# nrf7140_wificore register map
Vendor: Nordic Semiconductor; Series: nRF71; File version: 1
Registers are 32-bit, read-write, reset 0x0 unless marked. A register's access mark holds for its fields unless they carry their own. Offsets are from the block's base; [hi:lo] are bit positions; lines under a group give offsets from that group.

## RPUPHY (part 3 of 8) — WIFICore RPU PHY peripherals
Base 0x48080000; alternate view of RPUMAC
0x8000 WLAN_CTRL group — Unspecified
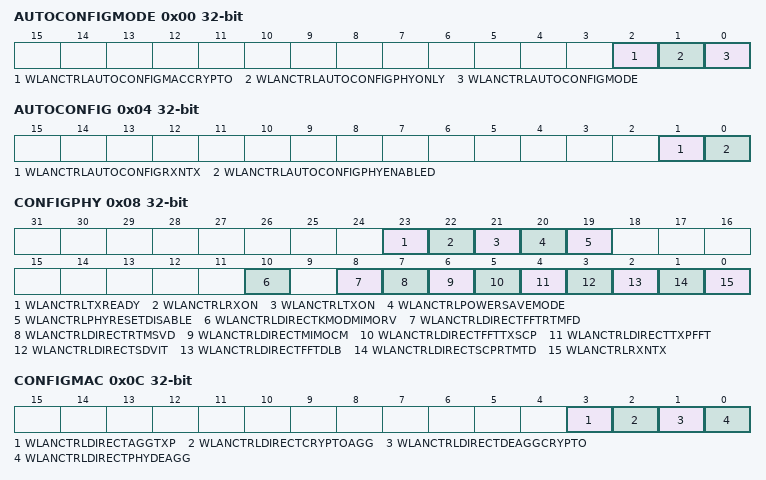
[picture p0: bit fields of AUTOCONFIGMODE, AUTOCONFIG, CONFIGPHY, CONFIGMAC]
  0x00 AUTOCONFIGMODE — WLAN CTRL AUTO CONFIG MODE
    [2] WLANCTRLAUTOCONFIGMACCRYPTO — Enable auto-configuration MAC with or without Crypto
      0=Auto-configure MAC pipeline with Crypto; 1=AutoConfigureMacPip1 (Auto-configure MAC pipeline without Crypto)
    [1] WLANCTRLAUTOCONFIGPHYONLY — Enable auto-configuration for PHY+MAC or PHY-only
      0=Auto-configure full PHY+MAC pipeline; 1=Auto-configure only PHY pipeline
    [0] WLANCTRLAUTOCONFIGMODE — Select mode used for automatic configuration:
      0=Automatic PHY configuration through WLAN_CTRL_AUTO_CONFIG register; 1=AutomaticPhyConfigur1 (Automatic PHY configuration using direct lines from MAC controller)
  0x04 AUTOCONFIG — WLAN CTRL AUTO CONFIG
    [1] WLANCTRLAUTOCONFIGRXNTX — Configure Wi-Fi RX or TX mode:
      0=Tx; 1=Rx
    [0] WLANCTRLAUTOCONFIGPHYENABLED — Enable PHY for either RX or TX:
      0=PhyDisabled; 1=PhyEnabled
  0x08 CONFIGPHY — WLAN CTRL CONFIG PHY
    [23] WLANCTRLTXREADY — Enable TX-SCP output:
      0=Disabled; 1=Enabled
    [22] WLANCTRLRXON — Set RF RX on:
      0=RxOff; 1=RxOn
    [21] WLANCTRLTXON — Set RF TX on:
      0=TxOff; 1=TxOn
    [20] WLANCTRLPOWERSAVEMODE — Enable Power Save mode:
      0=Disabled; 1=Enabled
    [19] WLANCTRLPHYRESETDISABLE — Control for automatic PHY reset (RX mode):
      0=PHY reset will be automatically generated; 1=No automatic PHY reset is generated
    [10] WLANCTRLDIRECTKMODMIMORV — Select whether MIMO RV input is from DMA channels or a direct connection between peripherals:
      0=DmaChannels; 1=Direct connection between peripherals
    [8] WLANCTRLDIRECTFFTRTMFD — Select whether FFT data input to RTM FD are from DMA channels or a direct connection from FFT:
      0=DmaChannels; 1=Direct connection between peripherals
    [7] WLANCTRLDIRECTRTMSVD — Select whether WLAN SVD input is from DMA channels or a direct connection between peripherals:
      0=DmaChannels; 1=Direct connection between peripherals
    [6] WLANCTRLDIRECTMIMOCM — Select whether MIMO Channel Matrix input is from DMA channels or a direct connection between peripherals:
      0=DmaChannels; 1=Direct connection between peripherals
    [5] WLANCTRLDIRECTFFTTXSCP — Select whether FFT output and TX-SCP input are to/from DMA channels or a direct connection between peripherals:
      0=DmaChannels; 1=Direct connection between peripherals
    [4] WLANCTRLDIRECTTXPFFT — Select whether TXP output and FFT input are to/from DMA channels or a direct connection between peripherals:
      0=DmaChannels; 1=Direct connection between peripherals
    [3] WLANCTRLDIRECTSDVIT — Select whether Stream Deparser outputs and Viterbi Decoder inputs are to/from DMA channels or a direct connection between peripherals:
      0=DmaChannels; 1=Direct connection between peripherals
    [2] WLANCTRLDIRECTFFTDLB — Select whether FFT output and DLB input are to/from DMA channels or a direct connection between peripherals:
      0=DmaChannels; 1=Direct connection between peripherals
    [1] WLANCTRLDIRECTSCPRTMTD — Select whether SCP outputs and RTM_TD input are to/from DMA channels or a direct connection between peripherals:
      0=DmaChannels; 1=Direct connection between peripherals
    [0] WLANCTRLRXNTX — Configure Wi-Fi RX or TX mode:
      0=Tx; 1=Rx
  0x0C CONFIGMAC — WLAN CTRL CONFIG MAC
    [all] fields
      0=DmaChannels; 1=Direct connection between peripherals
    [3] WLANCTRLDIRECTAGGTXP — Select whether Aggregation output and TXP input are to/from DMA channels or a direct connection between peripherals:
    [2] WLANCTRLDIRECTCRYPTOAGG — Select whether Crypto output and Aggregation input are to/from DMA channels or a direct connection between peripherals:
    [1] WLANCTRLDIRECTDEAGGCRYPTO — Select whether Deaggregation output and Crypto input are to/from DMA channels or a direct connection between peripherals:
    [0] WLANCTRLDIRECTPHYDEAGG — Select whether PHY outputs and Deaggregation inputs are to/from DMA channels or a direct connection between peripherals:
  0x10 TXHOLDOFF — WLAN CTRL TX HOLDOFF
    [13:0] WLANCTRLTXHOLDOFF — Specify TX hold-off to delay TX output to the DAC.Units are core clock cycles.
  0x14 TXEXTRAHOLDOFF — WLAN CTRL TX EXTRA HOLDOFF
    [13:0] WLANCTRLTXEXTRAHOLDOFF — Specify extra TX hold-off to delay TX output to the DAC.This extra hold-off can be selected through the TX vector.Units are core clock cycles.
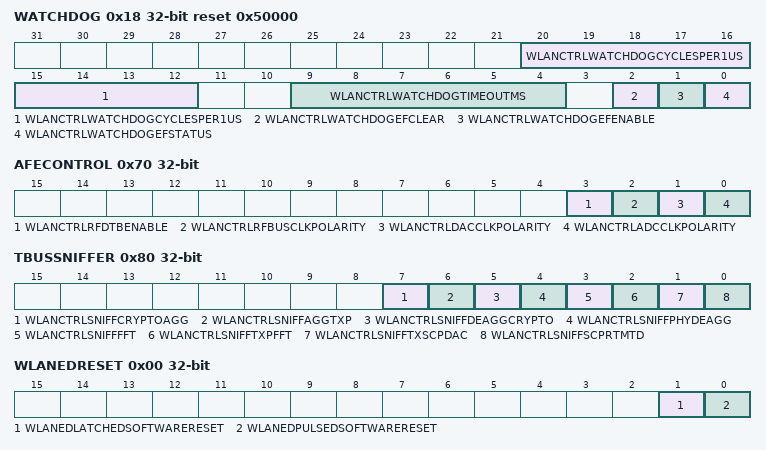
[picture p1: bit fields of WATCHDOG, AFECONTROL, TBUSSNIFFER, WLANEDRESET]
  0x18 WATCHDOG reset 0x50000 — WLAN CTRL WATCHDOG
    [20:12] WLANCTRLWATCHDOGCYCLESPER1US — Configure the number of core clock cycles per microsecond.
    [9:4] WLANCTRLWATCHDOGTIMEOUTMS — Specify watchdog timeout in milliseconds. Zero means the watchdog event flag is disabled.
    [2] WLANCTRLWATCHDOGEFCLEAR — WLAN watchdog event flag acknowledge/clear.Write 1 to clear WLAN_CTRL_WATCHDOG_EF_STATUS.Writing 0 has no effect.
    [1] WLANCTRLWATCHDOGEFENABLE — WLAN watchdog event flag enable.ANDed with WLAN_CTRL_WATCHDOG_EF_STATUS before generating EF output from block.
    [0] WLANCTRLWATCHDOGEFSTATUS — WLAN watchdog event flag status.Latched high when watchdog timer reaches programmed thresholdCan be forced high by writing 1 to this register for debug purposes (to test event flag connectivity in hardware and software).
  0x1C DEBUGPHYRESET ro — WLAN CTRL DEBUG PHY RESET
    [5:0] WLANCTRLDEBUGPHYRESET — Live state of the PHY reset signals0: PHY reset1: EDAGC reset2: SCP reset3: TD reset4: FD reset5: RXP reset
  0x20 DEBUGGING — WLAN CTRL DEBUG
    [1:0] WLANCTRLDEBUG — Enable debug registers PHY_VALID, PHY_ENABLE, MAC_VALID and MAC_ENABLE
      0=Disabled; 1=ValidEnable; 2=Sticky(Valid), Sticky(Enable); 3=Valid & Enable, Sticky(Valid & Enable)
  0x24 DEBUGPHYVALID ro — WLAN CTRL DEBUG PHY VALID
    [10:0] WLANCTRLDEBUGPHYVALID — Live state of the PHY valid flow control signals0: TXFD Input1: TXFD Output2: RXTD Input3: RXTD OFDM Output4: RXTD DSSS Output5: FFT Input6: FFT Output7: TXTD Input8: TXTD Output9: RXFD FFT Input10: RXFD Output
  0x28 DEBUGPHYENABLE ro — WLAN CTRL DEBUG PHY ENABLE
    [10:0] WLANCTRLDEBUGPHYENABLE — Live state of the PHY enable flow control signals0: TXFD Input1: TXFD Output2: RXTD Input3: RXTD OFDM Output4: RXTD DSSS Output5: FFT Input6: FFT Output7: TXTD Input8: TXTD Output9: RXFD FFT Input10: RXFD Output
  0x2C DEBUGMACVALID ro — WLAN CTRL DEBUG MAC VALID
    [6:0] WLANCTRLDEBUGMACVALID — Live state of the MAC valid flow control signals0: AGG WR1: AGG RD2: DEAGG WR3: DEAGG RD4: CRYPTO WR5: CRYPTO RD6: DECOMP WR
  0x30 DEBUGMACENABLE ro — WLAN CTRL DEBUG MAC ENABLE
    [6:0] WLANCTRLDEBUGMACENABLE — Live state of the MAC enable flow control signals0: AGG WR1: AGG RD2: DEAGG WR3: DEAGG RD4: CRYPTO WR5: CRYPTO RD6: DECOMP WR
  0x34 CCABUSYCOUNT0 — WLAN CTRL CCA BUSY COUNT 0
    [0] WLANCTRLCCABUSYCOUNTENA — Enable / disable CCA busy window counter. When disabled counter is set to zero.
  0x38 CCABUSYCOUNT1 ro — WLAN CTRL CCA BUSY COUNT 1
    [23:0] WLANCTRLCCABUSYCOUNTER — CCA busy window counter in Core clock cycles.
  0x3C NUMPAYLOADBYTESFORDEASSERTION — WLAN CTRL NUM PAYLOAD BYTES FOR DEASSERTION
    [5:0] WLANCTRLNUMPAYLOADBYTESFORDEASSERTION — Number of payload bytes after which PHY_RX_Request is deasserted.This value is set such that PHY-RX-Request is asserted till MAC hardware checkswhether MAC address of receiving packet is matching with expected address,i.e., this number should cover more than 10 bytes of MPDU.Typical value is 20 considering A-MPDU and some margin for MAC address matching.
  0x40 TMCOUNTERMSB — WLAN CTRL TM COUNTER MSB
    [23:0] WLANCTRLTMCOUNTERMSB — MSB of Counter used for time measurement snapshots
  0x44 TMCOUNTERLSB — WLAN CTRL TM COUNTER LSB
    [23:0] WLANCTRLTMCOUNTERLSB — LSB of Counter used for time measurement snapshots
  0x48 ADCFIRSTSAMPLESNAPSHOTMSB ro — WLAN CTRL ADC FIRST SAMPLE SNAPSHOT MSB
    [23:0] WLANCTRLADCFIRSTSAMPLESNAPSHOTMSB — MSB of snapshot of time measurement counter, taken when first sample of ADC goes valid
  0x4C ADCFIRSTSAMPLESNAPSHOTLSB ro — WLAN CTRL ADC FIRST SAMPLE SNAPSHOT LSB
    [23:0] WLANCTRLADCFIRSTSAMPLESNAPSHOTLSB — LSB of snapshot of time measurement counter, taken when first sample of ADC goes valid
  0x50 TMCOUNTERCTRL — WLAN CTRL TM COUNTER CTRL
    [0] WLANCTRLTMCOUNTERENABLE — Enable signal for 48-bit time measurement counter
  0x54 TXABORTCONTROL — WLAN CTRL TX ABORT CONTROL
    [0] WLANCTRLTXABORTCONTROL — Control to assert wlan_ctrl_rx_on when TX_ABORT is received.
      0=Do not assert wlan_ctrl_rx_on; 1=Assert wlan_ctrl_rx_on when abort_status is high
  0x58 OFDMRTMSCPEOPSNAPSHOTMSB ro — WLAN CTRL OFDM RTM SCP EOP SNAPSHOT MSB
    [23:0] WLANCTRLOFDMRTMSCPEOPSNAPSHOTMSB — MSB of snapshot of time measurement counter, taken when OFDM Receiver Training Mode - SCP EOP goes high
  0x5C OFDMRTMSCPEOPSNAPSHOTLSB ro — WLAN CTRL OFDM RTM SCP EOP SNAPSHOT LSB
    [23:0] WLANCTRLOFDMRTMSCPEOPSNAPSHOTLSB — LSB of snapshot of time measurement counter, taken when OFDM Receiver Training Mode - SCP EOP goes high
  0x60 OFDMRTMFDEOPSNAPSHOTMSB ro — WLAN CTRL OFDM RTM FD EOP SNAPSHOT MSB
    [23:0] WLANCTRLOFDMRTMFDEOPSNAPSHOTMSB — MSB of snapshot of time measurement counter, taken when OFDM Receiver Training Mode - FD EOP goes high
  0x64 OFDMRTMFDEOPSNAPSHOTLSB ro — WLAN CTRL OFDM RTM FD EOP SNAPSHOT LSB
    [23:0] WLANCTRLOFDMRTMFDEOPSNAPSHOTLSB — LSB of snapshot of time measurement counter, taken when OFDM Receiver Training Mode - FD EOP goes high
  0x68 TMCOUNTERSNAPSHOTMSB — WLAN CTRL TM COUNTER SNAPSHOT MSB
    [23:0] WLANCTRLTMCOUNTERSNAPSHOTMSB — MSB of snapshot of time measurement counter, taken when either WLAN_CTRL_TM_COUNTER_SNAPSHOT_MSB or WLAN_CTRL_TM_COUNTER_SNAPSHOT_LSB is written
  0x6C TMCOUNTERSNAPSHOTLSB — WLAN CTRL TM COUNTER SNAPSHOT LSB
    [23:0] WLANCTRLTMCOUNTERSNAPSHOTLSB — LSB of snapshot of time measurement counter, taken when either WLAN_CTRL_TM_COUNTER_SNAPSHOT_MSB or WLAN_CTRL_TM_COUNTER_SNAPSHOT_LSB is written
  0x70 AFECONTROL — WLAN CTRL AFE CONTROL
    [3] WLANCTRLRFDTBENABLE — RF Digital Test Bus enable
      0=RfDtbNotEnabled; 1=RfDrbEnabled
    [2] WLANCTRLRFBUSCLKPOLARITY — RF bus clock polarity:
      0=PositiveEdge; 1=NegativeEdge
    [1] WLANCTRLDACCLKPOLARITY — DAC sample clock polarity:
      0=PositiveEdge; 1=NegativeEdge
    [0] WLANCTRLADCCLKPOLARITY — ADC sample clock polarity:
      0=PositiveEdge; 1=NegativeEdge
  0x74 RFPMUUP — WLAN CTRL RF PMU UP
    [0] WLANCTRLRFPMUUP — Enable RF:
      0=Not enabled (PMU_UP_P=0 and PMU_UP_N=1); 1=Enabled (PMU_UP_P=1 and PMU_UP_N=0)
  0x78 RFBANDSEL — WLAN CTRL RF BAND SEL
    [0] WLANCTRLRFBANDSEL — Select between low band and high band RF:
      0=LowBand; 1=HighBand
  0x80 TBUSSNIFFER — WLAN CTRL TBUS SNIFFER
    [all] fields
      0=NotSniffed; 1=Sniff Tbus connection whilst in direct connection
    [7] WLANCTRLSNIFFCRYPTOAGG — Select whether Crypto outputs and Agg input are output to the EDC during direct connection:
    [6] WLANCTRLSNIFFAGGTXP — Select whether AGG outputs and TXP input are output to the EDC during direct connection:
    [5] WLANCTRLSNIFFDEAGGCRYPTO — Select whether DEAGG outputs and CRYPTO input are output to the EDC during direct connection:
    [4] WLANCTRLSNIFFPHYDEAGG — Select whether PHY outputs and DEAGG input are output to the EDC during direct connection:
    [3] WLANCTRLSNIFFFFT — Select whether FFT outputs and MIMO/TXSCP input are output to the EDC during direct connection:
    [2] WLANCTRLSNIFFTXPFFT — Select whether TXP outputs and FFT input are output to the EDC during direct connection:
    [1] WLANCTRLSNIFFTXSCPDAC — Select whether TX-SCP outputs and DAC input are output to the EDC during direct connection:
    [0] WLANCTRLSNIFFSCPRTMTD — Select whether SCP outputs and RTM_TD input are output to the EDC during direct connection:
  0xFC WLANCOREREVISION ro
    [23:0] WLANCOREREVISION — WiFi Core revision : Major(8).Minor(8).Maintenance(8)
0x9000 WIFICOREED group — Unspecified
  0x00 WLANEDRESET
    [1] WLANEDLATCHEDSOFTWARERESET — Latched software reset.
    [0] WLANEDPULSEDSOFTWARERESET — Self-clearing software reset.
  0x04 WLANEDFSMCONFIG reset 0x1
    [0] EDENABLE — Enable the ED module.
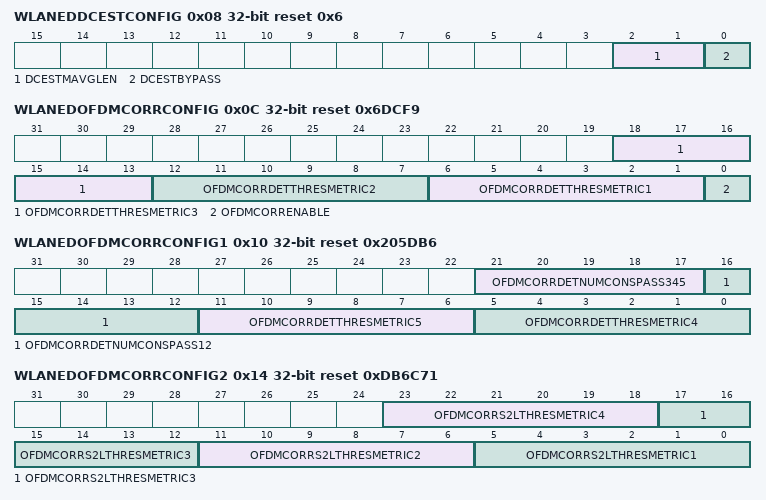
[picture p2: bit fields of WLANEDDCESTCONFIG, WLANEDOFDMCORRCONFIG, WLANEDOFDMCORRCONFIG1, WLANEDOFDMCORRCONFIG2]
  0x08 WLANEDDCESTCONFIG reset 0x6
    [2:1] DCESTMAVGLEN — DC estimation moving averager filter length:
      0=1; 1=2; 2=4; 3=8
    [0] DCESTBYPASS — Enable the WLAN ED DC EST module.
  0x0C WLANEDOFDMCORRCONFIG reset 0x6DCF9
    [18:13] OFDMCORRDETTHRESMETRIC3 — OFDM correlation detection metric 3 threshold. It has a range of -31 .. 0. Default value is -10.
    [12:7] OFDMCORRDETTHRESMETRIC2 — OFDM correlation detection metric 2 threshold. It has a range of -31 .. 0. Default value is -7.
    [6:1] OFDMCORRDETTHRESMETRIC1 — OFDM correlation detection metric 1 threshold. It has a range of -31 .. 0. Default value is -4.
    [0] OFDMCORRENABLE — Enable the WLAN ED OFDM correlation module.
  0x10 WLANEDOFDMCORRCONFIG1 reset 0x205DB6
    [21:17] OFDMCORRDETNUMCONSPASS345 — Number of consecutive metric pass for OFDM detection. It has a range of 0 .. 31.
    [16:12] OFDMCORRDETNUMCONSPASS12 — Number of consecutive metric pass for OFDM detection. It has a range of 0 .. 31.
    [11:6] OFDMCORRDETTHRESMETRIC5 — OFDM correlation detection metric 5 threshold. It has a range of -31 .. 0. Default value is -10.
    [5:0] OFDMCORRDETTHRESMETRIC4 — OFDM correlation detection metric 4 threshold. It has a range of -31 .. 0. Default value is -10.
  0x14 WLANEDOFDMCORRCONFIG2 reset 0xDB6C71
    [23:18] OFDMCORRS2LTHRESMETRIC4 — OFDM correlation S2l metric 4 threshold. It has a range of -31 .. 0. Default value is -10.
    [17:12] OFDMCORRS2LTHRESMETRIC3 — OFDM correlation S2l metric 3 threshold. It has a range of -31 .. 0. Default value is -10.
    [11:6] OFDMCORRS2LTHRESMETRIC2 — OFDM correlation S2l metric 2 threshold. It has a range of -31 .. 0. Default value is -15.
    [5:0] OFDMCORRS2LTHRESMETRIC1 — OFDM correlation S2l metric 1 threshold. It has a range of -31 .. 0. Default value is -15.
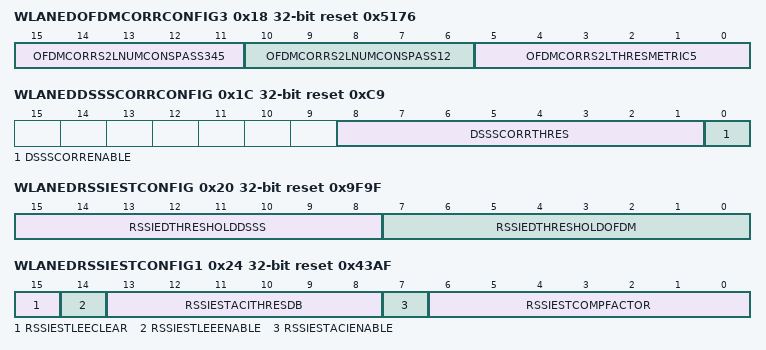
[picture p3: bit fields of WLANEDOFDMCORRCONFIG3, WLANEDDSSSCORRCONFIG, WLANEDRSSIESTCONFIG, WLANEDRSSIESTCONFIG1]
  0x18 WLANEDOFDMCORRCONFIG3 reset 0x5176
    [15:11] OFDMCORRS2LNUMCONSPASS345 — Number of consecutive pass for S2L detection. It has a range of 0 .. 31.
    [10:6] OFDMCORRS2LNUMCONSPASS12 — Number of consecutive pass for S2L detection. It has a range of 0 .. 31.
    [5:0] OFDMCORRS2LTHRESMETRIC5 — OFDM correlation S2l metric 5 threshold. It has a range of -31 .. 0. Default value is -10.
  0x1C WLANEDDSSSCORRCONFIG reset 0xC9
    [8:1] DSSSCORRTHRES — DSSS correlation threshold. It has a range of 0 .. 255.
    [0] DSSSCORRENABLE — Enable the WLAN ED DSSS correlation module.
  0x20 WLANEDRSSIESTCONFIG reset 0x9F9F
    [15:8] RSSIEDTHRESHOLDDSSS — RSSI estimation threshold (dBm) to be used when dsssDetected is true. It has a range of -128 .. 127. Default value is -97.
    [7:0] RSSIEDTHRESHOLDOFDM — RSSI estimation threshold (dBm) to be used when ofdmDetected is true. It has a range of -128 .. 127. Default value is -97.
  0x24 WLANEDRSSIESTCONFIG1 reset 0x43AF
    [15] RSSIESTLEECLEAR — Clear Low Energy Event.
    [14] RSSIESTLEEENABLE — Enable Low Energy Event.
    [13:8] RSSIESTACITHRESDB — RSSI estimation ACI dB threshold. It has a range of 0 .. 63.
    [7] RSSIESTACIENABLE — Enable Adjacent Channel Interference.
    [6:0] RSSIESTCOMPFACTOR — RSSI estimation compensation factor (F) in dB.It has a range of 0 .. 127.This is used in computing the RSSI given the variance and corresponding analog gain in dB.rssiInDbm = varDb - gainDb - RSSI_EST_COMP_FACTOR
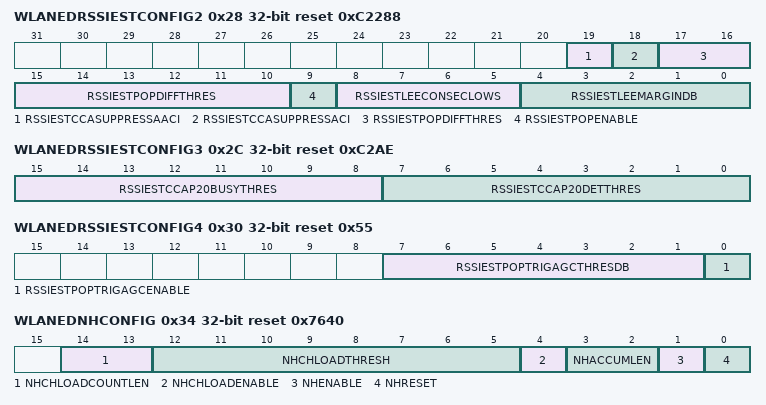
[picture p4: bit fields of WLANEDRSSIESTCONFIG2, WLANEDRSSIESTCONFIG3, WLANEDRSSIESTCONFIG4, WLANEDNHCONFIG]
  0x28 WLANEDRSSIESTCONFIG2 reset 0xC2288
    [19] RSSIESTCCASUPPRESSAACI — If this bit is '1', then CCA will be suppressed ('0') if AACI detected signal is '1'. Else CCA behaves normally.
    [18] RSSIESTCCASUPPRESSACI — If this bit is '1', then CCA will be suppressed ('0') if ACI detected signal is '1'. Else CCA behaves normally.
    [17:10] RSSIESTPOPDIFFTHRES — Packet over packet difference threshold. It has a range of 0 .. 255.
    [9] RSSIESTPOPENABLE — Enable Packet Over Packet.
    [8:5] RSSIESTLEECONSECLOWS — Number of consecutive lows for Low Energy Event. It has a range of 0 .. 15.
    [4:0] RSSIESTLEEMARGINDB — Low Energy Event dB margin. It has a range of 0 .. 31.
  0x2C WLANEDRSSIESTCONFIG3 reset 0xC2AE
    [15:8] RSSIESTCCAP20BUSYTHRES — Clear Channel Assessment busy threshold. It has a range of -127 .. 0. Default value is -62.
    [7:0] RSSIESTCCAP20DETTHRES — Clear Channel Assessment detection threshold. It has a range of -127 .. 0. Default value is -82.
  0x30 WLANEDRSSIESTCONFIG4 reset 0x55
    [7:1] RSSIESTPOPTRIGAGCTHRESDB — POP trigger for AGC threshold. It has a range of 0 .. 127. Default value is 42.
    [0] RSSIESTPOPTRIGAGCENABLE — Enable POP trigger generation for AGC when POP event.
  0x34 WLANEDNHCONFIG reset 0x7640
    [14:13] NHCHLOADCOUNTLEN — Noise histogram channel load length:
      0=2121; 1=2161; 2=2201; 3=2241
    [12:5] NHCHLOADTHRESH — Noise histogram channel load threshold. It has a range from -127 .. 0.
    [4] NHCHLOADENABLE — Enable noise histogram channel load counter.
    [3:2] NHACCUMLEN — Set the noise histogram accumulation length:
      0=2101; 1=2151; 2=2181; 3=2201
    [1] NHENABLE — Enable the noise histogram computation (Enable RSSI estimation accumulation).
    [0] NHRESET — Reset the noise histogram accumulator.
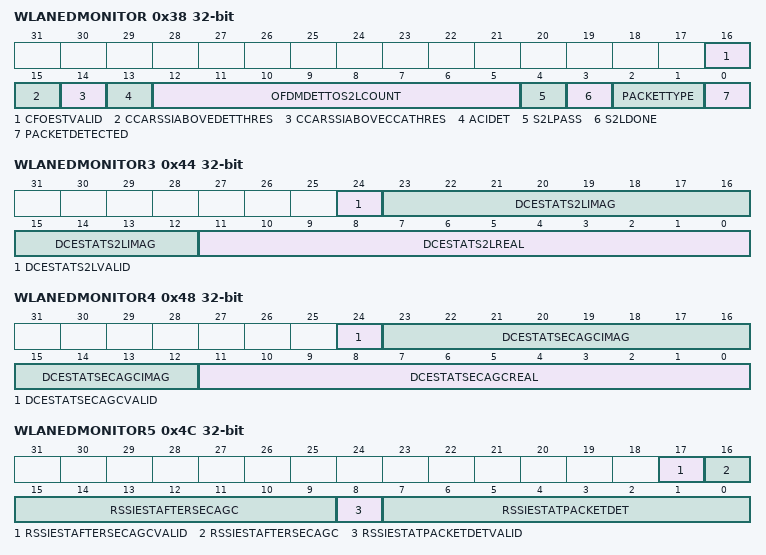
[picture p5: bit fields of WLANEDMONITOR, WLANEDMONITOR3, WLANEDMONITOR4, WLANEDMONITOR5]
  0x38 WLANEDMONITOR ro
    [16] CFOESTVALID — '1' indicates CFO estimation is completed
    [15] CCARSSIABOVEDETTHRES — '1' indicates the RSSI is above the Detection threshold (-82dBm)
    [14] CCARSSIABOVECCATHRES — '1' indicates the RSSI is above the CCA threshold (-62dBm)
    [13] ACIDET — '1' indicates an ACI signal is present and hence ED detections will not happen
    [12:5] OFDMDETTOS2LCOUNT — Contains the count in num of 20MHz samples from the time pktDetected happens to s2lPass
    [4] S2LPASS — Holds the value of s2l pass/fail status. If '1' s2l Pass, '0' s2l fail(timeout). This is valid only when S2L_EVENT is high
    [3] S2LDONE — '1' indicates s2l Event has occurred (either s2lPass or s2lFail)
    [2:1] PACKETTYPE — Indicates the type of packet detected:
      0=Unknown; 1=Ofdm; 2=Dsss
    [0] PACKETDETECTED — '1' indicates either OFDM/DSSS packet has been detected and TD processing is in progress
  0x3C WLANEDMONITOR1 ro
    [23:0] CFOESTATS2LREAL — ( 24-bit complex (s23.0)) Real part of CFO estimation e^j.theeta, where theeta = (2**pi**fHz**16/20e6) - fHz is CFO in Hz .
  0x40 WLANEDMONITOR2 ro
    [23:0] CFOESTATS2LIMAG — ( 24-bit complex (s23.0)) Imaginary part of CFO estimation e^j.theeta, where theeta = (2**pi**fHz**16/20e6) - fHz is CFO in Hz .
  0x44 WLANEDMONITOR3 ro
    [24] DCESTATS2LVALID — DC estimation at s2L detection valid flag.
    [23:12] DCESTATS2LIMAG — Imag part of DC estimation at s2L detection (12-bit complex (s9.2)).
    [11:0] DCESTATS2LREAL — Real part of DC estimation at s2L detection (12-bit complex (s9.2)).
  0x48 WLANEDMONITOR4 ro
    [24] DCESTATSECAGCVALID — DC estimation at second AGC valid flag.
    [23:12] DCESTATSECAGCIMAG — Imag part of DC estimation at second AGC (12-bit complex (s9.2)).
    [11:0] DCESTATSECAGCREAL — Real part of DC estimation at second AGC (12-bit complex (s9.2)).
  0x4C WLANEDMONITOR5 ro
    [17] RSSIESTAFTERSECAGCVALID — RSSI estimation after second AGC valid flag.
    [16:9] RSSIESTAFTERSECAGC — RSSI estimation after second AGC (s7.0).
    [8] RSSIESTATPACKETDETVALID — RSSI estimation at packet detection valid flag.
    [7:0] RSSIESTATPACKETDET — RSSI estimation at packet detection (s7.0).
  0x50 WLANEDMONITOR6 ro
    [23:0] NHACCUMVALUE — Noise histogram accumulation value. It has a range of 0 .. (2^24)-1. The average noise power in dBm is got by NH_ACCUM_VALUE/NH_ACCUM_COUNT.
  0x54 WLANEDMONITOR7 ro
    [19:0] NHACCUMCOUNT — Noise histogram accumulation count. It has a range of 0 .. (2^20)-1.The average noise power in dBm is got by NH_ACCUM_VALUE/NH_ACCUM_COUNT.
  0x58 WLANEDMONITOR8 ro
    [23:0] NHCHANNELLOADCOUNT — Noise histogram channel load count. It has a range of 0 .. (2^24)-1.
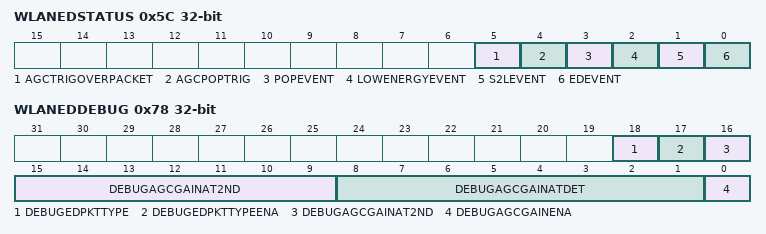
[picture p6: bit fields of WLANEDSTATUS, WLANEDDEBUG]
  0x5C WLANEDSTATUS ro
    [5] AGCTRIGOVERPACKET — AGC trigger Event after packet detection (equivalent to POP_EVENT). If this register contains a '1' in real time, it means the AgcTrigger event has not been cleared by PHY indicating a lockup.
    [4] AGCPOPTRIG — Packet Over Packet indication to AGC. If this register contains a '1' in real time, it means the AGC in-progess has not been set after a POP event indicating a lockup.
    [3] POPEVENT — Packet Over Packet event. If this register contains a '1' in real time, it means the POP event has not been cleared by PHY indicating a lockup.
    [2] LOWENERGYEVENT — Low Energy Event has happened (Jammer disappearance). If this register contains a '1' in real time, it means the LEE event has not been cleared by PHY indicating a lockup.
    [1] S2LEVENT — S2l Pass/Fail has happened. If this register contains a '1' in real time, it means the S2L event has not been cleared by PHY indicating a lockup.
    [0] EDEVENT — Packet detection has happened. If this register contains a '1' in real time, it means the ED event has not been cleared by PHY indicating a lockup.
  0x60 OFDMFIFOOVERFLOWSTALL
    [0] OFDMFIFOOVERFLOWSTALL — This field asserts if the ED ODFM FIFO has attempted to stall to prevent an overflow. Write any value to register to clear flag.
  0x64 OFDMFIFOUNDERFLOWSTALL
    [0] OFDMFIFOUNDERFLOWSTALL — This field asserts if the ED ODFM FIFO has attempted to stall to prevent an underflow. Write any value to register to clear flag.
  0x68 RSSIFIFOOVERFLOWSTALL
    [0] RSSIFIFOOVERFLOWSTALL — This field asserts if the ED RSSI FIFO has attempted to stall to prevent an overflow. Write any value to register to clear flag.
  0x6C RSSIFIFOUNDERFLOWSTALL
    [0] RSSIFIFOUNDERFLOWSTALL — This field asserts if the ED RSSI FIFO has attempted to stall to prevent an underflow. Write any value to register to clear flag.
  0x70 DATAFIFOOVERFLOWSTALL
    [0] DATAFIFOOVERFLOWSTALL — This field asserts if the ED DATA FIFO has attempted to stall to prevent an overflow. Write any value to register to clear flag.
  0x74 DATAFIFOUNDERFLOWSTALL
    [0] DATAFIFOUNDERFLOWSTALL — This field asserts if the ED DATA FIFO has attempted to stall to prevent an underflow. Write any value to register to clear flag.
  0x78 WLANEDDEBUG
    [18] DEBUGEDPKTTYPE — Forces the type of packet detected when DEBUG_ED_PKT_TYPE_ENA is set:
      0=Ofdm; 1=Dsss
    [17] DEBUGEDPKTTYPEENA — Enable ED Packet Type debug mode : overwrite packetType with values in DEBUG_ED_PKT_TYPE.
    [16:9] DEBUGAGCGAINAT2ND — AGC gain in dB at second agc (s7.0).
    [8:1] DEBUGAGCGAINATDET — AGC gain in dB at packet detection (s7.0).
    [0] DEBUGAGCGAINENA — Enable AGC gain debug mode : overwrite agcGainDb with values in DEBUG_AGC_GAIN_AT_DET and DEBUG_AGC_GAIN_AT_2ND (when 2nd agc is active).
